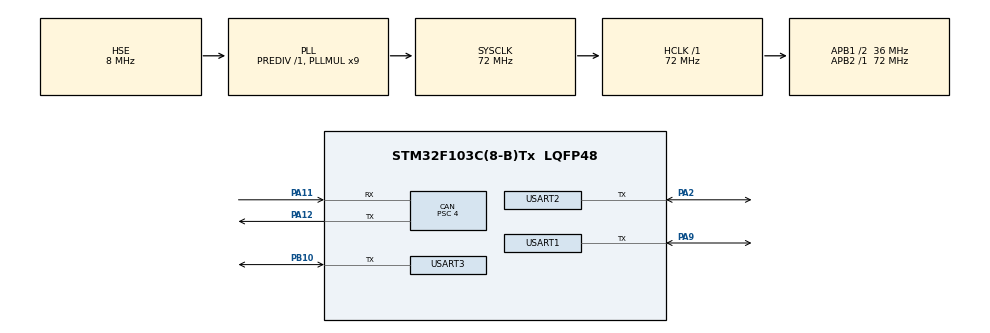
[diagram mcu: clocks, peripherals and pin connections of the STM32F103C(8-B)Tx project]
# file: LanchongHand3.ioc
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CAN.BS1=CAN_BS1_4TQ
CAN.BS2=CAN_BS2_4TQ
CAN.CalculateBaudRate=1000000
CAN.CalculateTimeBit=1000
CAN.CalculateTimeQuantum=111.11111111111111
CAN.Prescaler=4
Dma.Request0=USART1_RX
Dma.Request1=USART1_TX
Dma.Request2=USART2_RX
Dma.Request3=USART2_TX
Dma.Request4=USART3_RX
Dma.Request5=USART3_TX
Dma.USART1_RX.0.Direction=DMA_PERIPH_TO_MEMORY
Dma.USART1_RX.0.Instance=DMA1_Channel5
Dma.USART1_RX.0.MemDataAlignment=DMA_MDATAALIGN_BYTE
Dma.USART1_RX.0.MemInc=DMA_MINC_ENABLE
Dma.USART1_RX.0.Mode=DMA_NORMAL
Dma.USART1_RX.0.PeriphDataAlignment=DMA_PDATAALIGN_BYTE
Dma.USART1_RX.0.PeriphInc=DMA_PINC_DISABLE
Dma.USART1_RX.0.Priority=DMA_PRIORITY_LOW
Dma.USART1_TX.1.Direction=DMA_MEMORY_TO_PERIPH
Dma.USART1_TX.1.Instance=DMA1_Channel4
Dma.USART1_TX.1.MemDataAlignment=DMA_MDATAALIGN_BYTE
Dma.USART1_TX.1.MemInc=DMA_MINC_ENABLE
Dma.USART1_TX.1.Mode=DMA_NORMAL
Dma.USART1_TX.1.PeriphDataAlignment=DMA_PDATAALIGN_BYTE
Dma.USART1_TX.1.PeriphInc=DMA_PINC_DISABLE
Dma.USART1_TX.1.Priority=DMA_PRIORITY_LOW
Dma.USART2_RX.2.Direction=DMA_PERIPH_TO_MEMORY
Dma.USART2_RX.2.Instance=DMA1_Channel6
Dma.USART2_RX.2.MemDataAlignment=DMA_MDATAALIGN_BYTE
Dma.USART2_RX.2.MemInc=DMA_MINC_ENABLE
Dma.USART2_RX.2.Mode=DMA_NORMAL
Dma.USART2_RX.2.PeriphDataAlignment=DMA_PDATAALIGN_BYTE
Dma.USART2_RX.2.PeriphInc=DMA_PINC_DISABLE
Dma.USART2_RX.2.Priority=DMA_PRIORITY_LOW
Dma.USART2_TX.3.Direction=DMA_MEMORY_TO_PERIPH
Dma.USART2_TX.3.Instance=DMA1_Channel7
Dma.USART2_TX.3.MemDataAlignment=DMA_MDATAALIGN_BYTE
Dma.USART2_TX.3.MemInc=DMA_MINC_ENABLE
Dma.USART2_TX.3.Mode=DMA_NORMAL
Dma.USART2_TX.3.PeriphDataAlignment=DMA_PDATAALIGN_BYTE
Dma.USART2_TX.3.PeriphInc=DMA_PINC_DISABLE
Dma.USART2_TX.3.Priority=DMA_PRIORITY_LOW
Dma.USART3_RX.4.Direction=DMA_PERIPH_TO_MEMORY
Dma.USART3_RX.4.Instance=DMA1_Channel3
Dma.USART3_RX.4.MemDataAlignment=DMA_MDATAALIGN_BYTE
Dma.USART3_RX.4.MemInc=DMA_MINC_ENABLE
Dma.USART3_RX.4.Mode=DMA_NORMAL
Dma.USART3_RX.4.PeriphDataAlignment=DMA_PDATAALIGN_BYTE
Dma.USART3_RX.4.PeriphInc=DMA_PINC_DISABLE
Dma.USART3_RX.4.Priority=DMA_PRIORITY_LOW
Dma.USART3_TX.5.Direction=DMA_MEMORY_TO_PERIPH
Dma.USART3_TX.5.Instance=DMA1_Channel2
Dma.USART3_TX.5.MemDataAlignment=DMA_MDATAALIGN_BYTE
Dma.USART3_TX.5.MemInc=DMA_MINC_ENABLE
Dma.USART3_TX.5.Mode=DMA_NORMAL
Dma.USART3_TX.5.PeriphDataAlignment=DMA_PDATAALIGN_BYTE
Dma.USART3_TX.5.PeriphInc=DMA_PINC_DISABLE
Dma.USART3_TX.5.Priority=DMA_PRIORITY_LOW
FREERTOS.Queues01=Queue_CanPack,3,13,1,Static,Queue_CanPackBuffer,Queue_CanPackControlBlock;Queue_CanRxMsg,3,24,1,Static,Queue_CanRxMsgBuffer,Queue_CanRxMsgControlBlock
FREERTOS.Tasks01=defaultTask,24,128,StartDefaultTask,Default,NULL,Dynamic,NULL,NULL;Task_Usart_Rec,24,256,TaskUsartRec,As weak,NULL,Static,Task_Usart_RecBuffer,Task_Usart_RecControlBlock;Task_UsartTrans,24,256,TaskUsartTrans,As weak,NULL,Static,Task_UsartTransBuffer,Task_UsartTransControlBlock;Task_CAN_Rec,24,256,TaskCANRec,As weak,NULL,Static,Task_CAN_RecBuffer,Task_CAN_RecControlBlock;Task_CAN_Trans,24,256,TaskCANTrans,As weak,NULL,Static,Task_CAN_TransBuffer,Task_CAN_TransControlBlock
Mcu.Family=STM32F1
Mcu.Name=STM32F103C(8-B)Tx
Mcu.Package=LQFP48
NVIC.DMA1_Channel2_IRQn=true\:5\:0\:false\:false\:true\:true\:false\:true\:true
NVIC.DMA1_Channel3_IRQn=true\:5\:0\:false\:false\:true\:true\:false\:true\:true
NVIC.DMA1_Channel4_IRQn=true\:5\:0\:false\:false\:true\:true\:false\:true\:true
NVIC.DMA1_Channel5_IRQn=true\:5\:0\:false\:false\:true\:true\:false\:true\:true
NVIC.DMA1_Channel6_IRQn=true\:5\:0\:false\:false\:true\:true\:false\:true\:true
NVIC.DMA1_Channel7_IRQn=true\:5\:0\:false\:false\:true\:true\:false\:true\:true
NVIC.PriorityGroup=NVIC_PRIORITYGROUP_4
NVIC.TIM4_IRQn=true\:15\:0\:false\:false\:true\:false\:false\:true\:true
NVIC.TimeBase=TIM4_IRQn
NVIC.TimeBaseIP=TIM4
NVIC.USART1_IRQn=true\:5\:0\:false\:false\:true\:true\:false\:true\:true
NVIC.USART2_IRQn=true\:5\:0\:false\:false\:true\:true\:false\:true\:true
NVIC.USART3_IRQn=true\:5\:0\:false\:false\:true\:true\:false\:true\:true
NVIC.USB_LP_CAN1_RX0_IRQn=true\:5\:0\:false\:false\:true\:true\:true\:true\:true
PA11.Mode=CAN_Activate
PA11.Signal=CAN_RX
PA12.Mode=CAN_Activate
PA12.Signal=CAN_TX
PA13.Mode=Serial_Wire
PA13.Signal=SYS_JTMS-SWDIO
PA14.Mode=Serial_Wire
PA14.Signal=SYS_JTCK-SWCLK
PA2.Mode=Half_duplex(single_wire_mode)
PA2.Signal=USART2_TX
PA9.Mode=Half_duplex(single_wire_mode)
PA9.Signal=USART1_TX
PB10.Mode=Half_duplex(single_wire_mode)
PB10.Signal=USART3_TX
PD0-OSC_IN.Mode=HSE-External-Oscillator
PD0-OSC_IN.Signal=RCC_OSC_IN
PD1-OSC_OUT.Mode=HSE-External-Oscillator
PD1-OSC_OUT.Signal=RCC_OSC_OUT
ProjectManager.HeapSize=0x200
ProjectManager.StackSize=0x400
ProjectManager.TargetToolchain=MDK-ARM V5.32
RCC.AHBFreq_Value=72000000
RCC.APB1CLKDivider=RCC_HCLK_DIV2
RCC.APB1Freq_Value=36000000
RCC.APB1TimFreq_Value=72000000
RCC.APB2Freq_Value=72000000
RCC.APB2TimFreq_Value=72000000
RCC.HCLKFreq_Value=72000000
RCC.PLLMUL=RCC_PLL_MUL9
RCC.PLLSourceVirtual=RCC_PLLSOURCE_HSE
RCC.SYSCLKFreq_VALUE=72000000
RCC.SYSCLKSource=RCC_SYSCLKSOURCE_PLLCLK
RCC.USBFreq_Value=72000000
USART1.BaudRate=1000000
USART1.VirtualMode=VM_ASYNC
USART2.BaudRate=1000000
USART2.VirtualMode=VM_ASYNC
USART3.BaudRate=1000000
USART3.VirtualMode=VM_ASYNC
VP_FREERTOS_VS_CMSIS_V2.Mode=CMSIS_V2
VP_SYS_VS_tim4.Mode=TIM4
board=custom

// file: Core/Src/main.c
/* USER CODE BEGIN Header */
/**
  ******************************************************************************
  * @file           : main.c
  * @brief          : Main program body
  ******************************************************************************
  * @attention
  *
  * Copyright (c) 2026 STMicroelectronics.
  * All rights reserved.
  *
  * This software is licensed under terms that can be found in the LICENSE file
  * in the root directory of this software component.
  * If no LICENSE file comes with this software, it is provided AS-IS.
  *
  ******************************************************************************
  */
/* USER CODE END Header */
#include "main.h"
#include "cmsis_os.h"
#include "can.h"
#include "dma.h"
#include "usart.h"
#include "gpio.h"

void SystemClock_Config(void);
void MX_FREERTOS_Init(void);

int main(void)
{

  /* MCU Configuration--------------------------------------------------------*/

  /* Reset of all peripherals, Initializes the Flash interface and the Systick. */
	HAL_Init();

  /* Configure the system clock */
  SystemClock_Config();

  /* Initialize all configured peripherals */
  MX_GPIO_Init();
  MX_DMA_Init();
  MX_CAN_Init();
  MX_USART1_UART_Init();
  MX_USART2_UART_Init();
  MX_USART3_UART_Init();
  /* USER CODE BEGIN 2 */
	HAL_UART_MspDeInit(&huart1);
	HAL_UART_MspDeInit(&huart2);
	HAL_UART_MspDeInit(&huart3);
	WPZ_UART_MspInit(&huart1);
	WPZ_UART_MspInit(&huart2);
	WPZ_UART_MspInit(&huart3);

  /* USER CODE END 2 */

  /* Init scheduler */
  osKernelInitialize();  /* Call init function for freertos objects (in cmsis_os2.c) */
  MX_FREERTOS_Init();

  /* Start scheduler */
  osKernelStart();

  /* We should never get here as control is now taken by the scheduler */

  /* Infinite loop */
  while (1)
  {

  }
}

void SystemClock_Config(void)
{
  RCC_OscInitTypeDef RCC_OscInitStruct = {0};
  RCC_ClkInitTypeDef RCC_ClkInitStruct = {0};

  /** Initializes the RCC Oscillators according to the specified parameters
  * in the RCC_OscInitTypeDef structure.
  */
  RCC_OscInitStruct.OscillatorType = RCC_OSCILLATORTYPE_HSE;
  RCC_OscInitStruct.HSEState = RCC_HSE_ON;
  RCC_OscInitStruct.HSEPredivValue = RCC_HSE_PREDIV_DIV1;
  RCC_OscInitStruct.HSIState = RCC_HSI_ON;
  RCC_OscInitStruct.PLL.PLLState = RCC_PLL_ON;
  RCC_OscInitStruct.PLL.PLLSource = RCC_PLLSOURCE_HSE;
  RCC_OscInitStruct.PLL.PLLMUL = RCC_PLL_MUL9;
  if (HAL_RCC_OscConfig(&RCC_OscInitStruct) != HAL_OK)
  {
    Error_Handler();
  }

  /** Initializes the CPU, AHB and APB buses clocks
  */
  RCC_ClkInitStruct.ClockType = RCC_CLOCKTYPE_HCLK|RCC_CLOCKTYPE_SYSCLK
                              |RCC_CLOCKTYPE_PCLK1|RCC_CLOCKTYPE_PCLK2;
  RCC_ClkInitStruct.SYSCLKSource = RCC_SYSCLKSOURCE_PLLCLK;
  RCC_ClkInitStruct.AHBCLKDivider = RCC_SYSCLK_DIV1;
  RCC_ClkInitStruct.APB1CLKDivider = RCC_HCLK_DIV2;
  RCC_ClkInitStruct.APB2CLKDivider = RCC_HCLK_DIV1;

  if (HAL_RCC_ClockConfig(&RCC_ClkInitStruct, FLASH_LATENCY_2) != HAL_OK)
  {
    Error_Handler();
  }
}

void HAL_TIM_PeriodElapsedCallback(TIM_HandleTypeDef *htim)
{
  if (htim->Instance == TIM4)
  {
    HAL_IncTick();
  }
}

void Error_Handler(void)
{
  __disable_irq();
  while (1)
  {
  }
}

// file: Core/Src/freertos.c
/* USER CODE BEGIN Header */
/**
  ******************************************************************************
  * File Name          : freertos.c
  * Description        : Code for freertos applications
  ******************************************************************************
  * @attention
  *
  * Copyright (c) 2026 STMicroelectronics.
  * All rights reserved.
  *
  * This software is licensed under terms that can be found in the LICENSE file
  * in the root directory of this software component.
  * If no LICENSE file comes with this software, it is provided AS-IS.
  *
  ******************************************************************************
  */
/* USER CODE END Header */

#include "FreeRTOS.h"
#include "task.h"
#include "main.h"
#include "cmsis_os.h"

typedef StaticTask_t osStaticThreadDef_t;
typedef StaticQueue_t osStaticMessageQDef_t;

/* Definitions for defaultTask */
osThreadId_t defaultTaskHandle;
const osThreadAttr_t defaultTask_attributes = {
  .name = "defaultTask",
  .stack_size = 128 * 4,
  .priority = (osPriority_t) osPriorityNormal,
};
/* Definitions for Task_Usart_Rec */
osThreadId_t Task_Usart_RecHandle;
uint32_t Task_Usart_RecBuffer[ 256 ];
osStaticThreadDef_t Task_Usart_RecControlBlock;
const osThreadAttr_t Task_Usart_Rec_attributes = {
  .name = "Task_Usart_Rec",
  .cb_mem = &Task_Usart_RecControlBlock,
  .cb_size = sizeof(Task_Usart_RecControlBlock),
  .stack_mem = &Task_Usart_RecBuffer[0],
  .stack_size = sizeof(Task_Usart_RecBuffer),
  .priority = (osPriority_t) osPriorityNormal,
};
/* Definitions for Task_UsartTrans */
osThreadId_t Task_UsartTransHandle;
uint32_t Task_UsartTransBuffer[ 256 ];
osStaticThreadDef_t Task_UsartTransControlBlock;
const osThreadAttr_t Task_UsartTrans_attributes = {
  .name = "Task_UsartTrans",
  .cb_mem = &Task_UsartTransControlBlock,
  .cb_size = sizeof(Task_UsartTransControlBlock),
  .stack_mem = &Task_UsartTransBuffer[0],
  .stack_size = sizeof(Task_UsartTransBuffer),
  .priority = (osPriority_t) osPriorityNormal,
};
/* Definitions for Task_CAN_Rec */
osThreadId_t Task_CAN_RecHandle;
uint32_t Task_CAN_RecBuffer[ 256 ];
osStaticThreadDef_t Task_CAN_RecControlBlock;
const osThreadAttr_t Task_CAN_Rec_attributes = {
  .name = "Task_CAN_Rec",
  .cb_mem = &Task_CAN_RecControlBlock,
  .cb_size = sizeof(Task_CAN_RecControlBlock),
  .stack_mem = &Task_CAN_RecBuffer[0],
  .stack_size = sizeof(Task_CAN_RecBuffer),
  .priority = (osPriority_t) osPriorityNormal,
};
/* Definitions for Task_CAN_Trans */
osThreadId_t Task_CAN_TransHandle;
uint32_t Task_CAN_TransBuffer[ 256 ];
osStaticThreadDef_t Task_CAN_TransControlBlock;
const osThreadAttr_t Task_CAN_Trans_attributes = {
  .name = "Task_CAN_Trans",
  .cb_mem = &Task_CAN_TransControlBlock,
  .cb_size = sizeof(Task_CAN_TransControlBlock),
  .stack_mem = &Task_CAN_TransBuffer[0],
  .stack_size = sizeof(Task_CAN_TransBuffer),
  .priority = (osPriority_t) osPriorityNormal,
};
/* Definitions for Queue_CanPack */
osMessageQueueId_t Queue_CanPackHandle;
uint8_t Queue_CanPackBuffer[ 3 * 13 ];
osStaticMessageQDef_t Queue_CanPackControlBlock;
const osMessageQueueAttr_t Queue_CanPack_attributes = {
  .name = "Queue_CanPack",
  .cb_mem = &Queue_CanPackControlBlock,
  .cb_size = sizeof(Queue_CanPackControlBlock),
  .mq_mem = &Queue_CanPackBuffer,
  .mq_size = sizeof(Queue_CanPackBuffer)
};

void StartDefaultTask(void *argument);
void TaskUsartRec(void *argument);
void TaskUsartTrans(void *argument);
void TaskCANRec(void *argument);
void TaskCANTrans(void *argument);

void MX_FREERTOS_Init(void); /* (MISRA C 2004 rule 8.1) */

void MX_FREERTOS_Init(void) {

  /* Create the queue(s) */
  /* creation of Queue_CanPack */
  Queue_CanPackHandle = osMessageQueueNew (3, 13, &Queue_CanPack_attributes);

  /* Create the thread(s) */
  /* creation of defaultTask */
  defaultTaskHandle = osThreadNew(StartDefaultTask, NULL, &defaultTask_attributes);

  /* creation of Task_Usart_Rec */
  Task_Usart_RecHandle = osThreadNew(TaskUsartRec, NULL, &Task_Usart_Rec_attributes);

  /* creation of Task_UsartTrans */
  Task_UsartTransHandle = osThreadNew(TaskUsartTrans, NULL, &Task_UsartTrans_attributes);

  /* creation of Task_CAN_Rec */
  Task_CAN_RecHandle = osThreadNew(TaskCANRec, NULL, &Task_CAN_Rec_attributes);

  /* creation of Task_CAN_Trans */
  Task_CAN_TransHandle = osThreadNew(TaskCANTrans, NULL, &Task_CAN_Trans_attributes);

}

void StartDefaultTask(void *argument)
{
  for(;;)
  {
    osDelay(1);
  }
}

__weak void TaskUsartRec(void *argument)
{
  for(;;)
  {
    osDelay(1);
  }
}

__weak void TaskUsartTrans(void *argument)
{
  for(;;)
  {
    osDelay(1);
  }
}

__weak void TaskCANRec(void *argument)
{
  for(;;)
  {
    osDelay(1);
  }
}

__weak void TaskCANTrans(void *argument)
{
  for(;;)
  {
    osDelay(1);
  }
}
